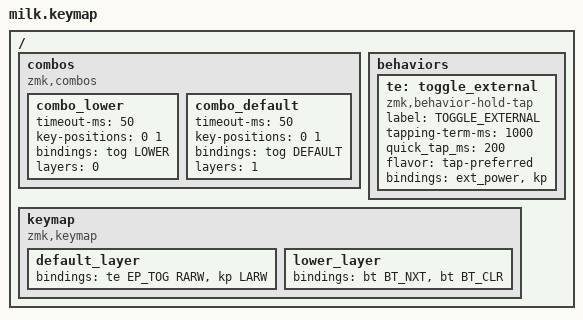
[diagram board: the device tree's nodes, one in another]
#include <behaviors.dtsi>
#include <dt-bindings/zmk/keys.h>
#include <dt-bindings/zmk/ext_power.h>
#include <dt-bindings/zmk/bt.h>
#define DEFAULT 0
#define LOWER   1
#define RAISE   2

/ {
    combos {
        compatible = "zmk,combos";
        combo_lower {
            timeout-ms = <50>;
            key-positions = <0 1>;
            bindings = <&tog LOWER>;
            layers = <0>;
        };

        combo_default {
            timeout-ms = <50>;
            key-positions = <0 1>;
            bindings = <&tog DEFAULT>;
            layers = <1>;
        };
    };

    behaviors {
        te: toggle_external {
            compatible = "zmk,behavior-hold-tap";
            label = "TOGGLE_EXTERNAL";
            #binding-cells = <2>;
            tapping-term-ms = <1000>;
            quick_tap_ms = <200>;
            flavor = "tap-preferred";
            bindings = <&ext_power>, <&kp>;
        };
    };

    keymap {
        compatible = "zmk,keymap";

        default_layer {
// ------ //
// | RT | //
// | LT | //
// ------ //

            bindings = <
    &te EP_TOG RARW
    &kp LARW
            >;
        };

        lower_layer {
// ------- //
// |BTNXT| //
// |BTCLR| //
// ------- //

            bindings = <
    &bt BT_NXT
    &bt BT_CLR
            >;
        };
    };
};
